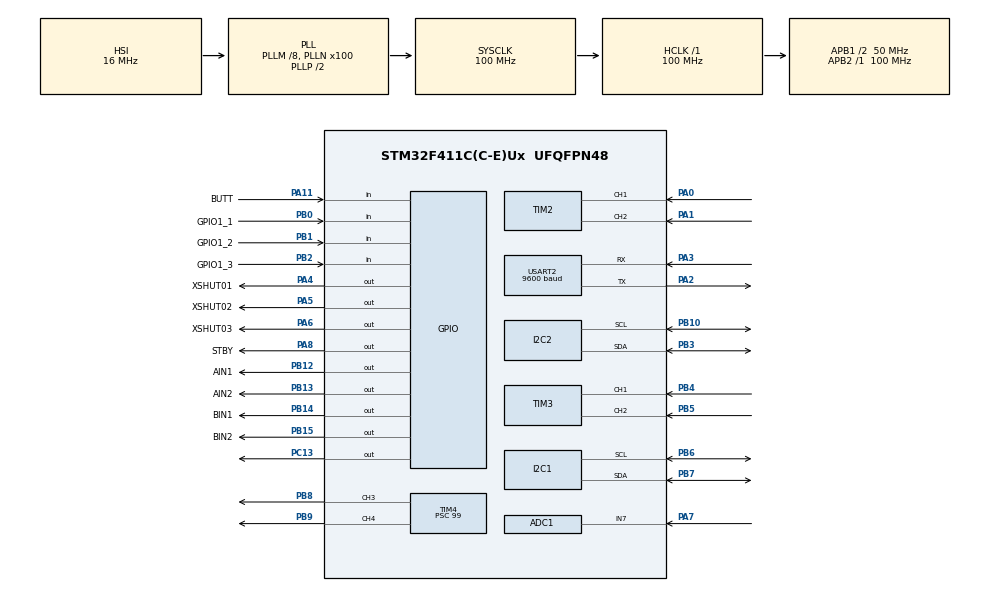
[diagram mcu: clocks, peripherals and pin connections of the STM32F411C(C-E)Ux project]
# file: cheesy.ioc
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ADC1.Channel-0\#ChannelRegularConversion=ADC_CHANNEL_7
ADC1.InjNumberOfConversion=0
ADC1.NbrOfConversion=1
ADC1.NbrOfConversionFlag=1
ADC1.Rank-0\#ChannelRegularConversion=1
ADC1.SamplingTime-0\#ChannelRegularConversion=ADC_SAMPLETIME_480CYCLES
ADC1.master=1
Dma.Request0=USART2_RX
Dma.USART2_RX.0.Direction=DMA_PERIPH_TO_MEMORY
Dma.USART2_RX.0.FIFOMode=DMA_FIFOMODE_DISABLE
Dma.USART2_RX.0.Instance=DMA1_Stream5
Dma.USART2_RX.0.MemDataAlignment=DMA_MDATAALIGN_BYTE
Dma.USART2_RX.0.MemInc=DMA_MINC_ENABLE
Dma.USART2_RX.0.Mode=DMA_NORMAL
Dma.USART2_RX.0.PeriphDataAlignment=DMA_PDATAALIGN_BYTE
Dma.USART2_RX.0.PeriphInc=DMA_PINC_DISABLE
Dma.USART2_RX.0.Priority=DMA_PRIORITY_LOW
I2C1.I2C_Mode=I2C_Fast
I2C2.I2C_Mode=I2C_Fast
Mcu.Family=STM32F4
Mcu.Name=STM32F411C(C-E)Ux
Mcu.Package=UFQFPN48
NVIC.DMA1_Stream5_IRQn=true\:0\:0\:false\:false\:true\:false\:true\:true
NVIC.PriorityGroup=NVIC_PRIORITYGROUP_4
NVIC.TIM1_UP_TIM10_IRQn=true\:0\:0\:false\:false\:true\:true\:true\:true
NVIC.USART2_IRQn=true\:0\:0\:false\:false\:true\:true\:true\:true
PA0-WKUP.Signal=S_TIM2_CH1_ETR
PA1.Signal=S_TIM2_CH2
PA11.GPIO_Label=BUTT
PA11.GPIO_PuPd=GPIO_PULLUP
PA11.Signal=GPIO_Input
PA13.Mode=Serial_Wire
PA13.Signal=SYS_JTMS-SWDIO
PA14.Mode=Serial_Wire
PA14.Signal=SYS_JTCK-SWCLK
PA2.Mode=Asynchronous
PA2.Signal=USART2_TX
PA3.Mode=Asynchronous
PA3.Signal=USART2_RX
PA4.GPIO_Label=XSHUT01
PA4.Signal=GPIO_Output
PA5.GPIO_Label=XSHUT02
PA5.Signal=GPIO_Output
PA6.GPIO_Label=XSHUT03
PA6.Signal=GPIO_Output
PA7.Signal=ADCx_IN7
PA8.GPIO_Label=STBY
PA8.Signal=GPIO_Output
PB0.GPIO_Label=GPIO1_1
PB0.Signal=GPIO_Input
PB1.GPIO_Label=GPIO1_2
PB1.Signal=GPIO_Input
PB10.Mode=I2C
PB10.Signal=I2C2_SCL
PB12.GPIO_Label=AIN1
PB12.Signal=GPIO_Output
PB13.GPIO_Label=AIN2
PB13.Signal=GPIO_Output
PB14.GPIO_Label=BIN1
PB14.Signal=GPIO_Output
PB15.GPIO_Label=BIN2
PB15.Signal=GPIO_Output
PB2.GPIO_Label=GPIO1_3
PB2.Signal=GPIO_Input
PB3.Mode=I2C
PB3.Signal=I2C2_SDA
PB4.Signal=S_TIM3_CH1
PB5.Signal=S_TIM3_CH2
PB6.Mode=I2C
PB6.Signal=I2C1_SCL
PB7.Mode=I2C
PB7.Signal=I2C1_SDA
PB8.Signal=S_TIM4_CH3
PB9.Signal=S_TIM4_CH4
PC13-ANTI_TAMP.Signal=GPIO_Output
PH0\ -\ OSC_IN.Mode=HSE-External-Oscillator
PH0\ -\ OSC_IN.Signal=RCC_OSC_IN
PH1\ -\ OSC_OUT.Mode=HSE-External-Oscillator
PH1\ -\ OSC_OUT.Signal=RCC_OSC_OUT
ProjectManager.HeapSize=0x200
ProjectManager.StackSize=0x400
ProjectManager.TargetToolchain=CMake
RCC.48MHZClocksFreq_Value=50000000
RCC.AHBFreq_Value=100000000
RCC.APB1CLKDivider=RCC_HCLK_DIV2
RCC.APB1Freq_Value=50000000
RCC.APB1TimFreq_Value=100000000
RCC.APB2Freq_Value=100000000
RCC.APB2TimFreq_Value=100000000
RCC.CortexFreq_Value=100000000
RCC.HCLKFreq_Value=100000000
RCC.HSE_VALUE=25000000
RCC.HSI_VALUE=16000000
RCC.LSE_VALUE=32768
RCC.PLLM=8
RCC.PLLN=100
RCC.SYSCLKFreq_VALUE=100000000
RCC.SYSCLKSource=RCC_SYSCLKSOURCE_PLLCLK
RCC.VCOOutputFreq_Value=200000000
SH.ADCx_IN7.0=ADC1_IN7,IN7
SH.S_TIM2_CH1_ETR.0=TIM2_CH1,Encoder_Interface
SH.S_TIM2_CH2.0=TIM2_CH2,Encoder_Interface
SH.S_TIM3_CH1.0=TIM3_CH1,Encoder_Interface
SH.S_TIM3_CH2.0=TIM3_CH2,Encoder_Interface
SH.S_TIM4_CH3.0=TIM4_CH3,PWM Generation3 CH3
SH.S_TIM4_CH4.0=TIM4_CH4,PWM Generation4 CH4
TIM10.Period=999
TIM10.Prescaler=999
TIM2.EncoderMode=TIM_ENCODERMODE_TI12
TIM2.IC1Filter=8
TIM2.IC2Filter=8
TIM3.EncoderMode=TIM_ENCODERMODE_TI12
TIM3.IC1Filter=8
TIM3.IC2Filter=8
TIM4.Channel-PWM\ Generation3\ CH3=TIM_CHANNEL_3
TIM4.Channel-PWM\ Generation4\ CH4=TIM_CHANNEL_4
TIM4.Period=999
TIM4.Prescaler=99
USART2.BaudRate=9600
USART2.VirtualMode=VM_ASYNC
VP_TIM10_VS_ClockSourceINT.Mode=Enable_Timer
board=custom

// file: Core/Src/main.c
/* USER CODE BEGIN Header */
/**
  ******************************************************************************
  * @file           : main.c
  * @brief          : Main program body
  ******************************************************************************
  * @attention
  *
  * Copyright (c) 2026 STMicroelectronics.
  * All rights reserved.
  *
  * This software is licensed under terms that can be found in the LICENSE file
  * in the root directory of this software component.
  * If no LICENSE file comes with this software, it is provided AS-IS.
  *
  ******************************************************************************
  */
/* USER CODE END Header */
#include "main.h"

/* USER CODE BEGIN Includes */
#include "motor_api.h"
#include "vl53l0x.h"
#include "imu.h"
#include "battery.h"
#include <math.h>
#include "app.h"

/* USER CODE END Includes */

ADC_HandleTypeDef hadc1;

I2C_HandleTypeDef hi2c1;
I2C_HandleTypeDef hi2c2;

TIM_HandleTypeDef htim2;
TIM_HandleTypeDef htim3;
TIM_HandleTypeDef htim4;
TIM_HandleTypeDef htim10;

UART_HandleTypeDef huart2;
DMA_HandleTypeDef hdma_usart2_rx;

void SystemClock_Config(void);
static void MX_GPIO_Init(void);
static void MX_DMA_Init(void);
static void MX_ADC1_Init(void);
static void MX_I2C2_Init(void);
static void MX_TIM2_Init(void);
static void MX_TIM4_Init(void);
static void MX_TIM3_Init(void);
static void MX_TIM10_Init(void);
static void MX_I2C1_Init(void);
static void MX_USART2_UART_Init(void);

/* USER CODE BEGIN 0 */
/* USER CODE BEGIN 0 */

/* USER CODE END 0 */

int main(void)
{

  /* MCU Configuration--------------------------------------------------------*/

  /* Reset of all peripherals, Initializes the Flash interface and the Systick. */
  HAL_Init();

  /* Configure the system clock */
  SystemClock_Config();

  /* Initialize all configured peripherals */
  MX_GPIO_Init();
  MX_DMA_Init();
  MX_ADC1_Init();
  MX_I2C2_Init();
  MX_TIM2_Init();
  MX_TIM4_Init();
  MX_TIM3_Init();
  MX_TIM10_Init();
  MX_I2C1_Init();
  MX_USART2_UART_Init();
  /* USER CODE BEGIN 2 */

  app_init();

  /* USER CODE END 2 */

  /* Infinite loop */
  /* USER CODE BEGIN WHILE */

  while (1)
  {

    app_loop();

    /* USER CODE END WHILE */

  }
}

void SystemClock_Config(void)
{
  RCC_OscInitTypeDef RCC_OscInitStruct = {0};
  RCC_ClkInitTypeDef RCC_ClkInitStruct = {0};

  /** Configure the main internal regulator output voltage
  */
  __HAL_RCC_PWR_CLK_ENABLE();
  __HAL_PWR_VOLTAGESCALING_CONFIG(PWR_REGULATOR_VOLTAGE_SCALE1);

  /** Initializes the RCC Oscillators according to the specified parameters
  * in the RCC_OscInitTypeDef structure.
  */
  RCC_OscInitStruct.OscillatorType = RCC_OSCILLATORTYPE_HSI;
  RCC_OscInitStruct.HSIState = RCC_HSI_ON;
  RCC_OscInitStruct.HSICalibrationValue = RCC_HSICALIBRATION_DEFAULT;
  RCC_OscInitStruct.PLL.PLLState = RCC_PLL_ON;
  RCC_OscInitStruct.PLL.PLLSource = RCC_PLLSOURCE_HSI;
  RCC_OscInitStruct.PLL.PLLM = 8;
  RCC_OscInitStruct.PLL.PLLN = 100;
  RCC_OscInitStruct.PLL.PLLP = RCC_PLLP_DIV2;
  RCC_OscInitStruct.PLL.PLLQ = 4;
  if (HAL_RCC_OscConfig(&RCC_OscInitStruct) != HAL_OK)
  {
    Error_Handler();
  }

  /** Initializes the CPU, AHB and APB buses clocks
  */
  RCC_ClkInitStruct.ClockType = RCC_CLOCKTYPE_HCLK|RCC_CLOCKTYPE_SYSCLK
                              |RCC_CLOCKTYPE_PCLK1|RCC_CLOCKTYPE_PCLK2;
  RCC_ClkInitStruct.SYSCLKSource = RCC_SYSCLKSOURCE_PLLCLK;
  RCC_ClkInitStruct.AHBCLKDivider = RCC_SYSCLK_DIV1;
  RCC_ClkInitStruct.APB1CLKDivider = RCC_HCLK_DIV2;
  RCC_ClkInitStruct.APB2CLKDivider = RCC_HCLK_DIV1;

  if (HAL_RCC_ClockConfig(&RCC_ClkInitStruct, FLASH_LATENCY_3) != HAL_OK)
  {
    Error_Handler();
  }
}

static void MX_ADC1_Init(void)
{

  ADC_ChannelConfTypeDef sConfig = {0};

  /** Configure the global features of the ADC (Clock, Resolution, Data Alignment and number of conversion)
  */
  hadc1.Instance = ADC1;
  hadc1.Init.ClockPrescaler = ADC_CLOCK_SYNC_PCLK_DIV4;
  hadc1.Init.Resolution = ADC_RESOLUTION_12B;
  hadc1.Init.ScanConvMode = DISABLE;
  hadc1.Init.ContinuousConvMode = DISABLE;
  hadc1.Init.DiscontinuousConvMode = DISABLE;
  hadc1.Init.ExternalTrigConvEdge = ADC_EXTERNALTRIGCONVEDGE_NONE;
  hadc1.Init.ExternalTrigConv = ADC_SOFTWARE_START;
  hadc1.Init.DataAlign = ADC_DATAALIGN_RIGHT;
  hadc1.Init.NbrOfConversion = 1;
  hadc1.Init.DMAContinuousRequests = DISABLE;
  hadc1.Init.EOCSelection = ADC_EOC_SINGLE_CONV;
  if (HAL_ADC_Init(&hadc1) != HAL_OK)
  {
    Error_Handler();
  }

  /** Configure for the selected ADC regular channel its corresponding rank in the sequencer and its sample time.
  */
  sConfig.Channel = ADC_CHANNEL_7;
  sConfig.Rank = 1;
  sConfig.SamplingTime = ADC_SAMPLETIME_480CYCLES;
  if (HAL_ADC_ConfigChannel(&hadc1, &sConfig) != HAL_OK)
  {
    Error_Handler();
  }

}

static void MX_I2C1_Init(void)
{

  hi2c1.Instance = I2C1;
  hi2c1.Init.ClockSpeed = 400000;
  hi2c1.Init.DutyCycle = I2C_DUTYCYCLE_2;
  hi2c1.Init.OwnAddress1 = 0;
  hi2c1.Init.AddressingMode = I2C_ADDRESSINGMODE_7BIT;
  hi2c1.Init.DualAddressMode = I2C_DUALADDRESS_DISABLE;
  hi2c1.Init.OwnAddress2 = 0;
  hi2c1.Init.GeneralCallMode = I2C_GENERALCALL_DISABLE;
  hi2c1.Init.NoStretchMode = I2C_NOSTRETCH_DISABLE;
  if (HAL_I2C_Init(&hi2c1) != HAL_OK)
  {
    Error_Handler();
  }

}

static void MX_I2C2_Init(void)
{

  hi2c2.Instance = I2C2;
  hi2c2.Init.ClockSpeed = 400000;
  hi2c2.Init.DutyCycle = I2C_DUTYCYCLE_2;
  hi2c2.Init.OwnAddress1 = 0;
  hi2c2.Init.AddressingMode = I2C_ADDRESSINGMODE_7BIT;
  hi2c2.Init.DualAddressMode = I2C_DUALADDRESS_DISABLE;
  hi2c2.Init.OwnAddress2 = 0;
  hi2c2.Init.GeneralCallMode = I2C_GENERALCALL_DISABLE;
  hi2c2.Init.NoStretchMode = I2C_NOSTRETCH_DISABLE;
  if (HAL_I2C_Init(&hi2c2) != HAL_OK)
  {
    Error_Handler();
  }

}

static void MX_TIM2_Init(void)
{

  TIM_Encoder_InitTypeDef sConfig = {0};
  TIM_MasterConfigTypeDef sMasterConfig = {0};

  htim2.Instance = TIM2;
  htim2.Init.Prescaler = 0;
  htim2.Init.CounterMode = TIM_COUNTERMODE_UP;
  htim2.Init.Period = 4294967295;
  htim2.Init.ClockDivision = TIM_CLOCKDIVISION_DIV1;
  htim2.Init.AutoReloadPreload = TIM_AUTORELOAD_PRELOAD_DISABLE;
  sConfig.EncoderMode = TIM_ENCODERMODE_TI12;
  sConfig.IC1Polarity = TIM_ICPOLARITY_RISING;
  sConfig.IC1Selection = TIM_ICSELECTION_DIRECTTI;
  sConfig.IC1Prescaler = TIM_ICPSC_DIV1;
  sConfig.IC1Filter = 8;
  sConfig.IC2Polarity = TIM_ICPOLARITY_RISING;
  sConfig.IC2Selection = TIM_ICSELECTION_DIRECTTI;
  sConfig.IC2Prescaler = TIM_ICPSC_DIV1;
  sConfig.IC2Filter = 8;
  if (HAL_TIM_Encoder_Init(&htim2, &sConfig) != HAL_OK)
  {
    Error_Handler();
  }
  sMasterConfig.MasterOutputTrigger = TIM_TRGO_RESET;
  sMasterConfig.MasterSlaveMode = TIM_MASTERSLAVEMODE_DISABLE;
  if (HAL_TIMEx_MasterConfigSynchronization(&htim2, &sMasterConfig) != HAL_OK)
  {
    Error_Handler();
  }

}

static void MX_TIM3_Init(void)
{

  TIM_Encoder_InitTypeDef sConfig = {0};
  TIM_MasterConfigTypeDef sMasterConfig = {0};

  htim3.Instance = TIM3;
  htim3.Init.Prescaler = 0;
  htim3.Init.CounterMode = TIM_COUNTERMODE_UP;
  htim3.Init.Period = 65535;
  htim3.Init.ClockDivision = TIM_CLOCKDIVISION_DIV1;
  htim3.Init.AutoReloadPreload = TIM_AUTORELOAD_PRELOAD_DISABLE;
  sConfig.EncoderMode = TIM_ENCODERMODE_TI12;
  sConfig.IC1Polarity = TIM_ICPOLARITY_RISING;
  sConfig.IC1Selection = TIM_ICSELECTION_DIRECTTI;
  sConfig.IC1Prescaler = TIM_ICPSC_DIV1;
  sConfig.IC1Filter = 8;
  sConfig.IC2Polarity = TIM_ICPOLARITY_RISING;
  sConfig.IC2Selection = TIM_ICSELECTION_DIRECTTI;
  sConfig.IC2Prescaler = TIM_ICPSC_DIV1;
  sConfig.IC2Filter = 8;
  if (HAL_TIM_Encoder_Init(&htim3, &sConfig) != HAL_OK)
  {
    Error_Handler();
  }
  sMasterConfig.MasterOutputTrigger = TIM_TRGO_RESET;
  sMasterConfig.MasterSlaveMode = TIM_MASTERSLAVEMODE_DISABLE;
  if (HAL_TIMEx_MasterConfigSynchronization(&htim3, &sMasterConfig) != HAL_OK)
  {
    Error_Handler();
  }

}

static void MX_TIM4_Init(void)
{

  TIM_MasterConfigTypeDef sMasterConfig = {0};
  TIM_OC_InitTypeDef sConfigOC = {0};

  htim4.Instance = TIM4;
  htim4.Init.Prescaler = 99;
  htim4.Init.CounterMode = TIM_COUNTERMODE_UP;
  htim4.Init.Period = 999;
  htim4.Init.ClockDivision = TIM_CLOCKDIVISION_DIV1;
  htim4.Init.AutoReloadPreload = TIM_AUTORELOAD_PRELOAD_DISABLE;
  if (HAL_TIM_PWM_Init(&htim4) != HAL_OK)
  {
    Error_Handler();
  }
  sMasterConfig.MasterOutputTrigger = TIM_TRGO_RESET;
  sMasterConfig.MasterSlaveMode = TIM_MASTERSLAVEMODE_DISABLE;
  if (HAL_TIMEx_MasterConfigSynchronization(&htim4, &sMasterConfig) != HAL_OK)
  {
    Error_Handler();
  }
  sConfigOC.OCMode = TIM_OCMODE_PWM1;
  sConfigOC.Pulse = 0;
  sConfigOC.OCPolarity = TIM_OCPOLARITY_HIGH;
  sConfigOC.OCFastMode = TIM_OCFAST_DISABLE;
  if (HAL_TIM_PWM_ConfigChannel(&htim4, &sConfigOC, TIM_CHANNEL_3) != HAL_OK)
  {
    Error_Handler();
  }
  if (HAL_TIM_PWM_ConfigChannel(&htim4, &sConfigOC, TIM_CHANNEL_4) != HAL_OK)
  {
    Error_Handler();
  }
  HAL_TIM_MspPostInit(&htim4);

}

static void MX_TIM10_Init(void)
{

  htim10.Instance = TIM10;
  htim10.Init.Prescaler = 999;
  htim10.Init.CounterMode = TIM_COUNTERMODE_UP;
  htim10.Init.Period = 999;
  htim10.Init.ClockDivision = TIM_CLOCKDIVISION_DIV1;
  htim10.Init.AutoReloadPreload = TIM_AUTORELOAD_PRELOAD_DISABLE;
  if (HAL_TIM_Base_Init(&htim10) != HAL_OK)
  {
    Error_Handler();
  }

}

static void MX_USART2_UART_Init(void)
{

  huart2.Instance = USART2;
  huart2.Init.BaudRate = 9600;
  huart2.Init.WordLength = UART_WORDLENGTH_8B;
  huart2.Init.StopBits = UART_STOPBITS_1;
  huart2.Init.Parity = UART_PARITY_NONE;
  huart2.Init.Mode = UART_MODE_TX_RX;
  huart2.Init.HwFlowCtl = UART_HWCONTROL_NONE;
  huart2.Init.OverSampling = UART_OVERSAMPLING_16;
  if (HAL_UART_Init(&huart2) != HAL_OK)
  {
    Error_Handler();
  }

}

static void MX_DMA_Init(void)
{

  /* DMA controller clock enable */
  __HAL_RCC_DMA1_CLK_ENABLE();

  /* DMA interrupt init */
  /* DMA1_Stream5_IRQn interrupt configuration */
  HAL_NVIC_SetPriority(DMA1_Stream5_IRQn, 0, 0);
  HAL_NVIC_EnableIRQ(DMA1_Stream5_IRQn);

}

static void MX_GPIO_Init(void)
{
  GPIO_InitTypeDef GPIO_InitStruct = {0};

  /* GPIO Ports Clock Enable */
  __HAL_RCC_GPIOC_CLK_ENABLE();
  __HAL_RCC_GPIOH_CLK_ENABLE();
  __HAL_RCC_GPIOA_CLK_ENABLE();
  __HAL_RCC_GPIOB_CLK_ENABLE();

  /*Configure GPIO pin Output Level */
  HAL_GPIO_WritePin(GPIOC, GPIO_PIN_13, GPIO_PIN_RESET);

  /*Configure GPIO pin Output Level */
  HAL_GPIO_WritePin(GPIOA, XSHUT01_Pin|XSHUT02_Pin|XSHUT03_Pin|STBY_Pin, GPIO_PIN_RESET);

  /*Configure GPIO pin Output Level */
  HAL_GPIO_WritePin(GPIOB, AIN1_Pin|AIN2_Pin|BIN1_Pin|BIN2_Pin, GPIO_PIN_RESET);

  /*Configure GPIO pin : PC13 */
  GPIO_InitStruct.Pin = GPIO_PIN_13;
  GPIO_InitStruct.Mode = GPIO_MODE_OUTPUT_PP;
  GPIO_InitStruct.Pull = GPIO_NOPULL;
  GPIO_InitStruct.Speed = GPIO_SPEED_FREQ_LOW;
  HAL_GPIO_Init(GPIOC, &GPIO_InitStruct);

  /*Configure GPIO pins : XSHUT01_Pin XSHUT02_Pin XSHUT03_Pin STBY_Pin */
  GPIO_InitStruct.Pin = XSHUT01_Pin|XSHUT02_Pin|XSHUT03_Pin|STBY_Pin;
  GPIO_InitStruct.Mode = GPIO_MODE_OUTPUT_PP;
  GPIO_InitStruct.Pull = GPIO_NOPULL;
  GPIO_InitStruct.Speed = GPIO_SPEED_FREQ_LOW;
  HAL_GPIO_Init(GPIOA, &GPIO_InitStruct);

  /*Configure GPIO pins : GPIO1_1_Pin GPIO1_2_Pin GPIO1_3_Pin */
  GPIO_InitStruct.Pin = GPIO1_1_Pin|GPIO1_2_Pin|GPIO1_3_Pin;
  GPIO_InitStruct.Mode = GPIO_MODE_INPUT;
  GPIO_InitStruct.Pull = GPIO_NOPULL;
  HAL_GPIO_Init(GPIOB, &GPIO_InitStruct);

  /*Configure GPIO pins : AIN1_Pin AIN2_Pin BIN1_Pin BIN2_Pin */
  GPIO_InitStruct.Pin = AIN1_Pin|AIN2_Pin|BIN1_Pin|BIN2_Pin;
  GPIO_InitStruct.Mode = GPIO_MODE_OUTPUT_PP;
  GPIO_InitStruct.Pull = GPIO_NOPULL;
  GPIO_InitStruct.Speed = GPIO_SPEED_FREQ_LOW;
  HAL_GPIO_Init(GPIOB, &GPIO_InitStruct);

  /*Configure GPIO pin : BUTT_Pin */
  GPIO_InitStruct.Pin = BUTT_Pin;
  GPIO_InitStruct.Mode = GPIO_MODE_INPUT;
  GPIO_InitStruct.Pull = GPIO_PULLUP;
  HAL_GPIO_Init(BUTT_GPIO_Port, &GPIO_InitStruct);

}

void Error_Handler(void)
{
  __disable_irq();
  while (1)
  {
  }
}
